# STM32WL5X_CM0P register map
File version: 2.1
CPU: CM0 r0p1, little endian, MPU, no FPU, 4 interrupt priority bits
Registers are 32-bit, read-write, reset 0x0 unless marked. A register's access mark holds for its fields unless they carry their own. Offsets are from the block's base; [hi:lo] are bit positions; {n}, {i} and the like mark numbered series; 'fields as' and 'values as' point back to an identical list.

## TIM1 — Advanced-control timers
Base 0x40012C00
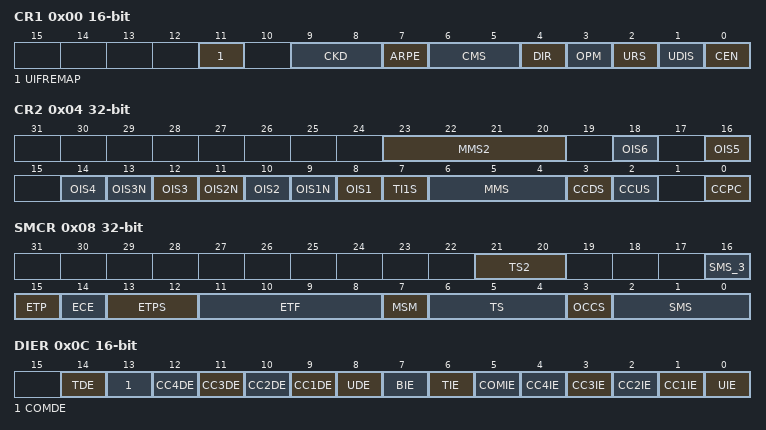
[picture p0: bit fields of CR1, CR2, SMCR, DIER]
0x00 CR1 16-bit — control register 1
  [11] UIFREMAP — UIF status bit remapping
    0=Disabled (No remapping. UIF status bit is not copied to TIMx_CNT register bit 31); 1=Enabled (Remapping enabled. UIF status bit is copied to TIMx_CNT register bit 31)
  [9:8] CKD — Clock division
    0=Div1 (t_DTS = t_CK_INT); 1=Div2 (t_DTS = 2 × t_CK_INT); 2=Div4 (t_DTS = 4 × t_CK_INT)
  [7] ARPE — Auto-reload preload enable
    0=Disabled (TIMx_APRR register is not buffered); 1=Enabled (TIMx_APRR register is buffered)
  [6:5] CMS — Center-aligned mode selection
    0=EdgeAligned (The counter counts up or down depending on the direction bit); 1=CenterAligned1 (The counter counts up and down alternatively. Output compare interrupt flags are set only when the counter is counting down.); 2=CenterAligned2 (The counter counts up and down alternatively. Output compare interrupt flags are set only when the counter is counting up.); 3=CenterAligned3 (The counter counts up and down alternatively. Output compare interrupt flags are set both when the counter is counting up or down.)
  [4] DIR — Direction
    0=Up (Counter used as upcounter); 1=Down (Counter used as downcounter)
  [3] OPM — One pulse mode
    0=Disabled (Counter is not stopped at update event); 1=Enabled (Counter stops counting at the next update event (clearing the CEN bit))
  [2] URS — Update request source
    0=AnyEvent (Any of counter overflow/underflow, setting UG, or update through slave mode, generates an update interrupt or DMA request); 1=CounterOnly (Only counter overflow/underflow generates an update interrupt or DMA request)
  [1] UDIS — Update disable
    0=Enabled (Update event enabled); 1=Disabled (Update event disabled)
  [0] CEN — Counter enable
    0=Disabled (Counter disabled); 1=Enabled (Counter enabled)
0x04 CR2 — control register 2
  [23:20] MMS2 — Master mode selection 2
    0=Reset - the UG bit from the TIMx_EGR register is used as trigger output (TRGO2). If the reset is generated by the trigger input (slave mode controller configured in reset mode), the signal on TRGO2 is delayed compared to the actual reset; 1=Enable - the Counter Enable signal CNT_EN is used as trigger output (TRGO2). It is useful to start several timers at the same time or to control a window in which a slave timer is enabled. The Counter Enable signal is generated by a logic AND between the CEN control bit and the trigger input when configured in Gated mode. When the Counter Enable signal is controlled by the trigger input, there is a delay on TRGO2, except if the Master/Slave mode is selected (see the MSM bit description in TIMx_SMCR register); 2=Update - the update event is selected as trigger output (TRGO2). For instance, a master timer can then be used as a prescaler for a slave timer; 3=Compare pulse - the trigger output sends a positive pulse when the CC1IF flag is to be set (even if it was already high), as soon as a capture or compare match occurs (TRGO2); {v}=Compare - OC{v-3}REFC signal is used as trigger output (TRGO2) (v=4..9); 10=PulseOC4 (Compare Pulse - OC4REFC rising or falling edges generate pulses on TRGO2); 11=PulseOC6 (Compare Pulse - OC6REFC rising or falling edges generate pulses on TRGO2); 12=RisingOC4_6 (Compare Pulse - OC4REFC or OC6REFC rising edges generate pulses on TRGO2); 13=RisingOC4_FallingOC6 (Compare Pulse - OC4REFC rising or OC6REFC falling edges generate pulses on TRGO2); 14=RisingOC5_6 (Compare Pulse - OC5REFC or OC6REFC rising edges generate pulses on TRGO2); 15=RisingOC5_FallingOC6 (Compare Pulse - OC5REFC rising or OC6REFC falling edges generate pulses on TRGO2)
  [2n+7] OIS{n}N (n=1..3) — Output Idle state (OC{n}N output)
    0=Reset (OCxN=0 after a dead-time when MOE=0); 1=Set (OCxN=1 after a dead-time when MOE=0)
  [2n+6] OIS{n} (n=1..6) — Output Idle state (OC{n} output)
    0=Reset (OCx=0 (after a dead-time if OCx(N) is implemented) when MOE=0); 1=Set (OCx=1 (after a dead-time if OCx(N) is implemented) when MOE=0)
  [7] TI1S — TI1 selection
    0=Normal (The TIMx_CH1 pin is connected to TI1 input); 1=XOR (The TIMx_CH1, CH2, CH3 pins are connected to TI1 input)
  [6:4] MMS — Master mode selection
    0=Reset (The UG bit from the TIMx_EGR register is used as trigger output); 1=Enable (The counter enable signal, CNT_EN, is used as trigger output); 2=Update (The update event is selected as trigger output); 3=ComparePulse (The trigger output send a positive pulse when the CC1IF flag it to be set, as soon as a capture or a compare match occurred); {v}=CompareOC{v-3} (OC{v-3}REF signal is used as trigger output) (v=4..7)
  [3] CCDS — Capture/compare DMA selection
    0=OnCompare (CCx DMA request sent when CCx event occurs); 1=OnUpdate (CCx DMA request sent when update event occurs)
  [2] CCUS — Capture/compare control update selection
    0=Sw (When capture/compare control bits are preloaded (CCPC=1), they are updated by setting the COMG bit only); 1=SwOrEdge (When capture/compare control bits are preloaded (CCPC=1), they are updated by setting the COMG bit or when an rising edge occurs on TRGI)
  [0] CCPC — Capture/compare preloaded control
    0=NotPreloaded (CCxE, CCxNE and OCxM bits are not preloaded); 1=Preloaded (CCxE, CCxNE and OCxM bits are preloaded)
0x08 SMCR — slave mode control register
  [21:20] TS2 — Trigger selection
  [16] SMS_3 — Slave mode selection
    0=Disabled (Slave mode disabled (see SMS[0:2])); 1=CombinedResetTrigger (SMS[0:2] must be 0b000 (DisabledOrCombined). Combined reset + trigger mode - Rising edge of the selected trigger input (TRGI) reinitializes the counter, generates an update of the registers and starts the counter)
  [15] ETP — External trigger polarity
    0=NotInverted (ETR is noninverted, active at high level or rising edge); 1=Inverted (ETR is inverted, active at low level or falling edge)
  [14] ECE — External clock enable
    0=Disabled (External clock mode 2 disabled); 1=Enabled (External clock mode 2 enabled. The counter is clocked by any active edge on the ETRF signal.)
  [13:12] ETPS — External trigger prescaler
    0=Div1 (Prescaler OFF); 1=Div2 (ETRP frequency divided by 2); 2=Div4 (ETRP frequency divided by 4); 3=Div8 (ETRP frequency divided by 8)
  [11:8] ETF — External trigger filter
    0=No filter, sampling is done at fDTS; 1=FCK_INT_N2 (fSAMPLING=fCK_INT, N=2); 2=FCK_INT_N4 (fSAMPLING=fCK_INT, N=4); 3=FCK_INT_N8 (fSAMPLING=fCK_INT, N=8); 4=FDTS_Div2_N6 (fSAMPLING=fDTS/2, N=6); 5=FDTS_Div2_N8 (fSAMPLING=fDTS/2, N=8); 6=FDTS_Div4_N6 (fSAMPLING=fDTS/4, N=6); 7=FDTS_Div4_N8 (fSAMPLING=fDTS/4, N=8); 8=FDTS_Div8_N6 (fSAMPLING=fDTS/8, N=6); 9=FDTS_Div8_N8 (fSAMPLING=fDTS/8, N=8); 10=FDTS_Div16_N5 (fSAMPLING=fDTS/16, N=5); 11=FDTS_Div16_N6 (fSAMPLING=fDTS/16, N=6); 12=FDTS_Div16_N8 (fSAMPLING=fDTS/16, N=8); 13=FDTS_Div32_N5 (fSAMPLING=fDTS/32, N=5); 14=FDTS_Div32_N6 (fSAMPLING=fDTS/32, N=6); 15=FDTS_Div32_N8 (fSAMPLING=fDTS/32, N=8)
  [7] MSM — Master/slave mode
    0=NoSync (No action); 1=Sync (The effect of an event on the trigger input (TRGI) is delayed to allow a perfect synchronization between the current timer and its slaves (through TRGO). It is useful if we want to synchronize several timers on a single external event)
  [6:4] TS — Trigger selection
    0=ITR0 (Internal Trigger 0 (ITR0)); 1=ITR1 (Internal Trigger 1 (ITR1)); 2=ITR2 (Internal Trigger 2 (ITR2)); 4=TI1F_ED (TI1 Edge Detector (TI1F_ED)); 5=TI1FP1 (Filtered Timer Input 1 (TI1FP1)); 6=TI2FP2 (Filtered Timer Input 2 (TI2FP2)); 7=ETRF (External Trigger input (ETRF))
  [3] OCCS — OCREF clear selection
  [2:0] SMS — Slave mode selection
    0=DisabledOrCombined (Slave mode disabled - if CEN = ‘1 then the prescaler is clocked directly by the internal clock. If SMS[3]=1 then Combined reset + trigger mode - Rising edge of the selected trigger input (TRGI) reinitializes the counter, generates an update of the registers and starts the counter); 1=Encoder mode 1 - Counter counts up/down on TI2FP1 edge depending on TI1FP2 level; 2=Encoder mode 2 - Counter counts up/down on TI1FP2 edge depending on TI2FP1 level; 3=Encoder mode 3 - Counter counts up/down on both TI1FP1 and TI2FP2 edges depending on the level of the other input; 4=Reset Mode - Rising edge of the selected trigger input (TRGI) reinitializes the counter and generates an update of the registers; 5=Gated Mode - The counter clock is enabled when the trigger input (TRGI) is high. The counter stops (but is not reset) as soon as the trigger becomes low. Both start and stop of the counter are controlled; 6=Trigger Mode - The counter starts at a rising edge of the trigger TRGI (but it is not reset). Only the start of the counter is controlled; 7=ExtClockMode (External Clock Mode 1 - Rising edges of the selected trigger (TRGI) clock the counter)
0x0C DIER 16-bit — DMA/interrupt enable register
  [14] TDE — Trigger DMA request enable
    0=Disabled (Trigger DMA request disabled); 1=Enabled (Trigger DMA request enabled)
  [13] COMDE — COM DMA request enable
    0=Disabled (COM DMA request disabled); 1=Enabled (COM DMA request enabled)
  [n+8] CC{n}DE (n=1..4) — Capture/Compare {n} DMA request enable
    0=Disabled (CCx DMA request disabled); 1=Enabled (CCx DMA request enabled)
  [8] UDE — Update DMA request enable
    0=Disabled (Update DMA request disabled); 1=Enabled (Update DMA request enabled)
  [7] BIE — Break interrupt enable
    0=Disabled (Break interrupt disabled); 1=Enabled (Break interrupt enabled)
  [6] TIE — Trigger interrupt enable
    0=Disabled (Trigger interrupt disabled); 1=Enabled (Trigger interrupt enabled)
  [5] COMIE — COM interrupt enable
    0=Disabled (COM interrupt disabled); 1=Enabled (COM interrupt enabled)
  [n] CC{n}IE (n=1..4) — Capture/Compare {n} interrupt enable
    0=Disabled (CCx interrupt disabled); 1=Enabled (CCx interrupt enabled)
  [0] UIE — Update interrupt enable
    0=Disabled (Update interrupt disabled); 1=Enabled (Update interrupt enabled)
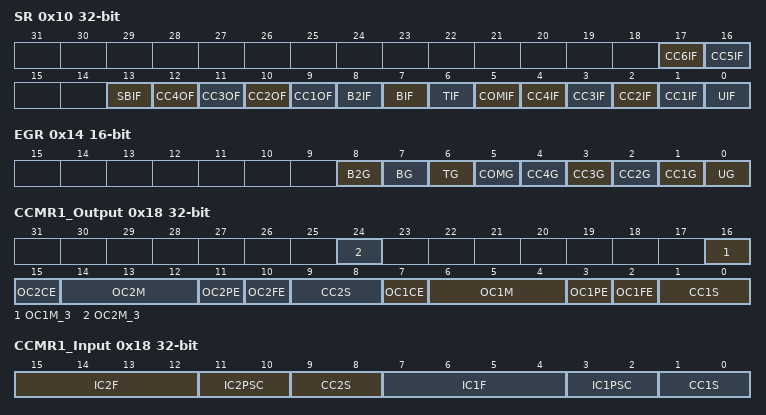
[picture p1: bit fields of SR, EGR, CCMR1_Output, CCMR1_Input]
0x10 SR — status register
  [17] CC6IF write-0-clears — Compare 6 interrupt flag
    on read: 0=NoMatch (No campture/compare has been detected); 1=Match (If CC1 is an output: The content of the counter TIMx_CNT matches the content of the TIMx_CCR1 register. If CC1 is an input: The counter value has been captured in TIMx_CCR1 register.) | on write: 0=Clear flag
  [16] CC5IF write-0-clears — Compare 5 interrupt flag
    values as CC6IF
  [13] SBIF write-0-clears — System Break interrupt flag
    on read: 0=NoTrigger (No break event occurred); 1=Trigger (An active level has been detected on the system break input. An interrupt is generated if BIE=1 in the TIMx_DIER register) | on write: 0=Clear flag
  [n+8] CC{n}OF (n=1..4) write-0-clears — Capture/Compare {n} overcapture flag
    on read: 0=No overcapture has been detected; 1=Overcapture (The counter value has been captured in TIMx_CCRx register while CCxIF flag was already set) | on write: 0=Clear flag
  [8] B2IF write-0-clears — Break 2 interrupt flag
    on read: 0=NoTrigger (No break event occurred); 1=Trigger (An active level has been detected on the break 2 input. An interrupt is generated if BIE=1 in the TIMx_DIER register) | on write: 0=Clear flag
  [7] BIF write-0-clears — Break interrupt flag
    on read: 0=NoTrigger (No break event occurred); 1=Trigger (An active level has been detected on the break input. An interrupt is generated if BIE=1 in the TIMx_DIER register) | on write: 0=Clear flag
  [6] TIF write-0-clears — Trigger interrupt flag
    on read: 0=No trigger event occurred; 1=Trigger interrupt pending | on write: 0=Clear flag
  [5] COMIF write-0-clears — COM interrupt flag
    on read: 0=No COM event occurred; 1=COM (COM interrupt pending) | on write: 0=Clear flag
  [n] CC{n}IF (n=1..4) write-0-clears — Capture/compare {n} interrupt flag
    values as CC6IF
  [0] UIF write-0-clears — Update interrupt flag
    on read: 0=NoUpdateOccurred; 1=UpdatePending (Update interrupt pending) | on write: 0=Clear flag
0x14 EGR 16-bit wo — event generation register
  [8] B2G — Break 2 generation
    1=Trigger (A break 2 event is generated. MOE bit is cleared and B2IF flag is set. Related interrupt can occur if enabled)
  [7] BG — Break generation
    1=Trigger (A break event is generated. MOE bit is cleared and BIF flag is set. Related interrupt or DMA transfer can occur if enabled)
  [6] TG — Trigger generation
    1=Trigger (The TIF flag is set in TIMx_SR register. Related interrupt or DMA transfer can occur if enabled.)
  [5] COMG — Capture/Compare control update generation
    1=Trigger (When CCPC bit is set, it allows CCxE, CCxNE and OCxM bits to be updated)
  [n] CC{n}G (n=1..4) — Capture/compare {n} generation
    1=Trigger (If CC1 is an output: CC1IF flag is set, Corresponding interrupt or DMA request is sent if enabled. If CC1 is an input: The current value of the counter is captured in TIMx_CCR1 register.)
  [0] UG — Update generation
    1=Update (Re-initializes the timer counter and generates an update of the registers.)
0x18 CCMR1_Output — capture/compare mode register 1 (output mode)
  [8n+8] OC{n}M_3 (n=1..2) — Output compare {n} mode, bit 3
    0=Normal output compare mode (modes 0-7); 1=Extended output compare mode (modes 7-15)
  [8n-1] OC{n}CE (n=1..2) — Output compare {n} clear enable
  [8n-2:8n-4] OC{n}M (n=1..2) — Output compare {n} mode
    0=Frozen (The comparison between the output compare register TIMx_CCRy and the counter TIMx_CNT has no effect on the outputs / OpmMode1: Retriggerable OPM mode 1 - In up-counting mode, the channel is active until a trigger event is detected (on TRGI signal). In down-counting mode, the channel is inactive); 1=ActiveOnMatch (Set channel to active level on match. OCyREF signal is forced high when the counter matches the capture/compare register / OpmMode2: Inversely to OpmMode1); 2=InactiveOnMatch (Set channel to inactive level on match. OCyREF signal is forced low when the counter matches the capture/compare register / Reserved); 3=Toggle (OCyREF toggles when TIMx_CNT=TIMx_CCRy / Reserved); 4=ForceInactive (OCyREF is forced low / CombinedPwmMode1: OCyREF has the same behavior as in PWM mode 1. OCyREFC is the logical OR between OC1REF and OC2REF); 5=ForceActive (OCyREF is forced high / CombinedPwmMode2: OCyREF has the same behavior as in PWM mode 2. OCyREFC is the logical AND between OC1REF and OC2REF); 6=PwmMode1 (In upcounting, channel is active as long as TIMx_CNT<TIMx_CCRy else inactive. In downcounting, channel is inactive as long as TIMx_CNT>TIMx_CCRy else active / AsymmetricPwmMode1: OCyREF has the same behavior as in PWM mode 1. OCyREFC outputs OC1REF when the counter is counting up, OC2REF when it is counting down); 7=PwmMode2 (Inversely to PwmMode1 / AsymmetricPwmMode2: Inversely to AsymmetricPwmMode1)
  [8n-5] OC{n}PE (n=1..2) — Output compare {n} preload enable
    0=Disabled (Preload register on CCRx disabled. New values written to CCRx are taken into account immediately); 1=Enabled (Preload register on CCRx enabled. Preload value is loaded into active register on each update event)
  [8n-6] OC{n}FE (n=1..2) — Output compare {n} fast enable
    0=Disabled (Fast output disabled); 1=Enabled (Fast output enabled)
  [8n-7:8n-8] CC{n}S (n=1..2) — Capture/Compare {n} selection
    0=Output (CCx channel is configured as output)
0x18 CCMR1_Input (alternate view of CCMR1_Output) — capture/compare mode register 1 (input mode)
  [9:8] CC2S — Capture/compare 2 selection
    1=TI2 (CC2 channel is configured as input, IC2 is mapped on TI2); 2=TI1 (CC2 channel is configured as input, IC2 is mapped on TI1); 3=TRC (CC2 channel is configured as input, IC2 is mapped on TRC)
  [8n-1:8n-4] IC{n}F (n=1..2) — Input capture {n} filter
    values as SMCR.ETF
  [8n-5:8n-6] IC{n}PSC (n=1..2) — Input capture {n} prescaler
    0=No prescaler, capture is done each time an edge is detected on the capture input; 1=TwoEvents (Capture is done once every 2 events); 2=FourEvents (Capture is done once every 4 events); 3=EightEvents (Capture is done once every 8 events)
  [1:0] CC1S — Capture/Compare 1 selection
    1=TI1 (CC1 channel is configured as input, IC1 is mapped on TI1); 2=TI2 (CC1 channel is configured as input, IC1 is mapped on TI2); 3=TRC (CC1 channel is configured as input, IC1 is mapped on TRC)
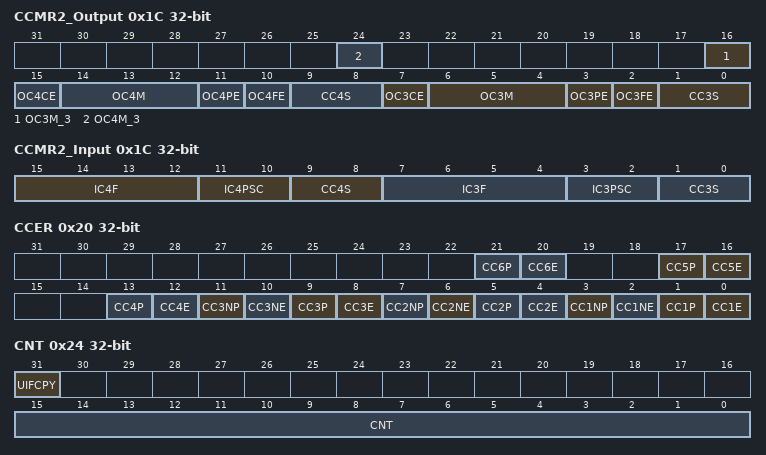
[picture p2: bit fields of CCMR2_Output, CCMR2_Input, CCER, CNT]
0x1C CCMR2_Output — capture/compare mode register 2 (output mode)
  [8n-8] OC{n}M_3 (n=3..4) — Output compare {n} mode, bit 3
    values as CCMR1_Output.OC1M_3
  [8n-17] OC{n}CE (n=3..4) — Output compare {n} clear enable
  [8n-18:8n-20] OC{n}M (n=3..4) — Output compare {n} mode
    values as CCMR1_Output.OC1M
  [8n-21] OC{n}PE (n=3..4) — Output compare {n} preload enable
    values as CCMR1_Output.OC1PE
  [8n-22] OC{n}FE (n=3..4) — Output compare {n} fast enable
    values as CCMR1_Output.OC1FE
  [8n-23:8n-24] CC{n}S (n=3..4) — Capture/Compare {n} selection
    0=Output (CCx channel is configured as output)
0x1C CCMR2_Input (alternate view of CCMR2_Output) — capture/compare mode register 2 (input mode)
  [9:8] CC4S — Capture/Compare 4 selection
    1=TI4 (CC4 channel is configured as input, IC4 is mapped on TI4); 2=TI3 (CC4 channel is configured as input, IC4 is mapped on TI3); 3=TRC (CC4 channel is configured as input, IC4 is mapped on TRC)
  [8n-17:8n-20] IC{n}F (n=3..4) — Input capture {n} filter
    values as SMCR.ETF
  [8n-21:8n-22] IC{n}PSC (n=3..4) — Input capture {n} prescaler
    values as CCMR1_Input.IC1PSC
  [1:0] CC3S — Capture/Compare 3 selection
    1=TI3 (CC3 channel is configured as input, IC3 is mapped on TI3); 2=TI4 (CC3 channel is configured as input, IC3 is mapped on TI4); 3=TRC (CC3 channel is configured as input, IC3 is mapped on TRC)
0x20 CCER — capture/compare enable register
  [4n-1] CC{n}NP (n=1..3) — Capture/Compare {n} output Polarity
    0=ActiveHigh (OCxN active high); 1=ActiveLow (OCxN active low)
  [4n-2] CC{n}NE (n=1..3) — Capture/Compare {n} complementary output enable
    0=Disabled (Complementary output disabled); 1=Enabled (Complementary output enabled)
  [4n-3] CC{n}P (n=1..6) — Capture/Compare {n} output Polarity
    0=RisingEdge (Noninverted/rising edge); 1=FallingEdge (Inverted/falling edge)
  [4n-4] CC{n}E (n=1..6) — Capture/Compare {n} output enable
    0=Disabled (Capture disabled); 1=Enabled (Capture enabled)
0x24 CNT access per field — counter
  [31] UIFCPY ro — UIF copy
  [15:0] CNT rw
0x24 CNT16 16-bit (alternate view of CNT) — 16-bit counter register
  [15:0] CNT — counter value
0x28 PSC 16-bit — prescaler
  [15:0] PSC — Prescaler value
0x2C ARR 16-bit reset 0xFFFF — auto-reload register
  [15:0] ARR — Auto-reload value
0x30 RCR — repetition counter register
  [15:0] REP — Repetition counter value
{0x30+4i} CCR{i} (i=1..4) 16-bit — capture/compare register
  [15:0] CCR — Capture/Compare value
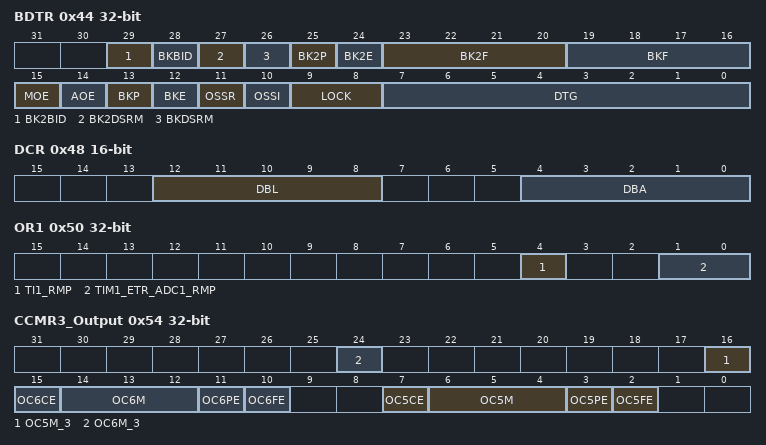
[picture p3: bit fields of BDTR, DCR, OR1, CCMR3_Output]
0x44 BDTR — break and dead-time register
  [29] BK2BID — Break2 bidirectional
    0=Input (Break input BRK2 in input mode); 1=Bidirectional (Break input BRK2 in bidirectional mode)
  [28] BKBID
    0=Input (Break input BRK in input mode); 1=Bidirectional (Break input BRK in bidirectional mode)
  [27] BK2DSRM — Break2 Disarm
    0=Armed (Break input BRK2 is armed); 1=Disarmed (Break input BRK2 is disarmed)
  [26] BKDSRM
    0=Armed (Break input BRK is armed); 1=Disarmed (Break input BRK is disarmed)
  [25] BK2P — Break 2 polarity
    0=ActiveLow (Break input BRKx is active low); 1=ActiveHigh (Break input BRKx is active high)
  [24] BK2E — Break 2 enable
    0=Disabled (Break function x disabled); 1=Enabled (Break function x enabled)
  [23:20] BK2F — Break 2 filter
    values as SMCR.ETF
  [19:16] BKF — Break filter
    values as SMCR.ETF
  [15] MOE — Main output enable
    0=DisabledIdle (OC/OCN are disabled or forced idle depending on OSSI); 1=Enabled (OC/OCN are enabled if CCxE/CCxNE are set)
  [14] AOE — Automatic output enable
    0=Manual (MOE can be set only by software); 1=Automatic (MOE can be set by software or automatically at the next update event (if none of the break inputs BRK and BRK2 is active))
  [13] BKP — Break polarity
    values as BK2P
  [12] BKE — Break enable
    values as BK2E
  [11] OSSR — Off-state selection for Run mode
    0=HiZ (When inactive, OC/OCN outputs are disabled); 1=IdleLevel (When inactive, OC/OCN outputs are enabled with their inactive level)
  [10] OSSI — Off-state selection for Idle mode
    0=HiZ (When inactive, OC/OCN outputs are disabled); 1=IdleLevel (When inactive, OC/OCN outputs are forced to idle level)
  [9:8] LOCK — Lock configuration
    0=Off (No bit is write protected); 1=Level1 (Any bits except MOE, OSSR, OSSI and LOCK in TIMx_BDTR register, OISx and OISxN bits in TIMx_CR2 register can no longer be written); 2=Level2 (LOCK Level 1 + CC Polarity bits (CCxP/CCxNP bits in TIMx_CCER register, as long as the related channel is configured in output through the CCxS bits) as well as OSSR and OSSI bits can no longer be written); 3=Level3 (LOCK Level 2 + CC Control bits (OCxM and OCxPE bits in TIMx_CCMRx registers, as long as the related channel is configured in output through the CCxS bits) can no longer be written)
  [7:0] DTG — Dead-time generator setup
0x48 DCR 16-bit — DMA control register
  [12:8] DBL range 0..17 — DMA burst length
  [4:0] DBA — DMA base address
0x4C DMAR — DMA address for full transfer
  [31:0] DMAB — DMA register for burst accesses
0x50 OR1 — option register 1
  [4] TI1_RMP — Input Capture 1 remap
    0=IO (TIM1 input capture 1 is connected to I/O); 1=COMP1 (TIM1 input capture 1 is connected to COMP1 output)
  [1:0] TIM1_ETR_ADC1_RMP — TIM1_ETR_ADC1 remapping capability
    0=Select (TIM1_ETR is not connected to ADC AWDx (must be selected when the ETR comes from the ETR input pin)); 1=ADC_AWD1 (TIM1_ETR is connected to ADC AWD1); 2=ADC_AWD2 (TIM1_ETR is connected to ADC AWD2); 3=ADC_AWD3 (TIM1_ETR is connected to ADC AWD3)
0x54 CCMR3_Output — capture/compare mode register 3
  [8n-24] OC{n}M_3 (n=5..6) — Output compare {n} mode, bit 3
    values as CCMR1_Output.OC1M_3
  [8n-33] OC{n}CE (n=5..6) — Output compare {n} clear enable
  [8n-34:8n-36] OC{n}M (n=5..6) — Output compare {n} mode
    values as CCMR1_Output.OC1M
  [8n-37] OC{n}PE (n=5..6) — Output compare {n} preload enable
    values as CCMR1_Output.OC1PE
  [8n-38] OC{n}FE (n=5..6) — Output compare {n} fast enable
    values as CCMR1_Output.OC1FE
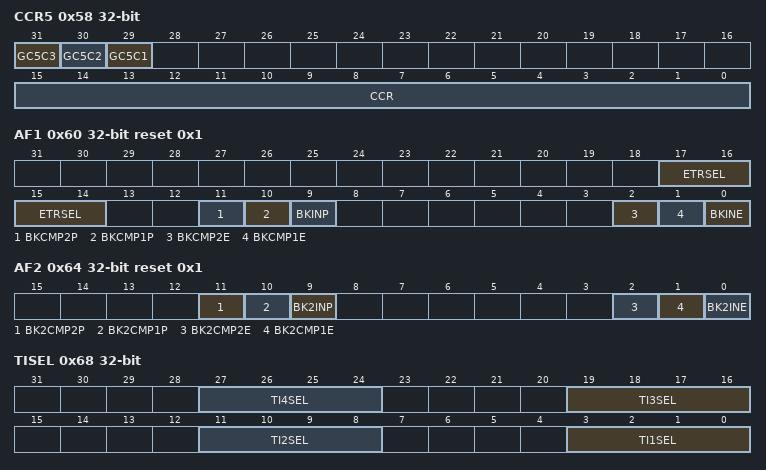
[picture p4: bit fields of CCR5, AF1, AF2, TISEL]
0x58 CCR5 — capture/compare register
  [31] GC5C3 — Group Channel 5 and Channel 3
    0=Disabled (No effect of OC5REF on OC3REFC); 1=Enabled (OC3REFC is the logical AND of OC3REFC and OC5REF)
  [30] GC5C2 — Group Channel 5 and Channel 2
    0=Disabled (No effect of OC5REF on OC2REFC); 1=Enabled (OC2REFC is the logical AND of OC2REFC and OC5REF)
  [29] GC5C1 — Group Channel 5 and Channel 1
    0=Disabled (No effect of OC5REF on OC1REFC); 1=Enabled (OC1REFC is the logical AND of OC1REFC and OC5REF)
  [15:0] CCR — Capture/Compare value
0x5C CCR6 16-bit — capture/compare register
  [15:0] CCR — Capture/Compare value
0x60 AF1 reset 0x1 — alternate function option register 1
  [17:14] ETRSEL — ETR source selection
    0=Legacy (ETR legacy mode); 1=COMP1 (COMP1 output); 2=COMP2 (COMP2 output)
  [11] BKCMP2P — BRK COMP2 input polarity
    0=NotInverted (Input polarity not inverted); 1=Inverted (Input polarity inverted)
  [10] BKCMP1P — BRK COMP1 input polarity
    values as BKCMP2P
  [9] BKINP — BRK BKIN input polarity
    values as BKCMP2P
  [2] BKCMP2E — BRK COMP2 enable
    0=Disabled (COMP2 input disabled); 1=Enabled (COMP2 input enabled)
  [1] BKCMP1E — BRK COMP1 enable
    0=Disabled (COMP1 input disabled); 1=Enabled (COMP1 input enabled)
  [0] BKINE — BRK BKIN input enable
    0=Disabled (BKIN input disabled); 1=Enabled (BKIN input enabled)
0x64 AF2 reset 0x1 — Alternate function register 2
  [11] BK2CMP2P — BRK2 COMP2 input polarity
    values as AF1.BKCMP2P
  [10] BK2CMP1P — BRK2 COMP1 input polarity
    values as AF1.BKCMP2P
  [9] BK2INP — BRK2 BKIN2 input polarity
    values as AF1.BKCMP2P
  [2] BK2CMP2E — BRK2 COMP2 enable
    values as AF1.BKCMP2E
  [1] BK2CMP1E — BRK2 COMP1 enable
    values as AF1.BKCMP1E
  [0] BK2INE — BRK2 BKIN input enable
    values as AF1.BKINE
0x68 TISEL — timer input selection register
  [all] fields
    0=Selected (TIM1_CHx input selected)
  [8n-5:8n-8] TI{n}SEL (n=1..4) — selects TI{n}[0] to TI{n}[15] input
